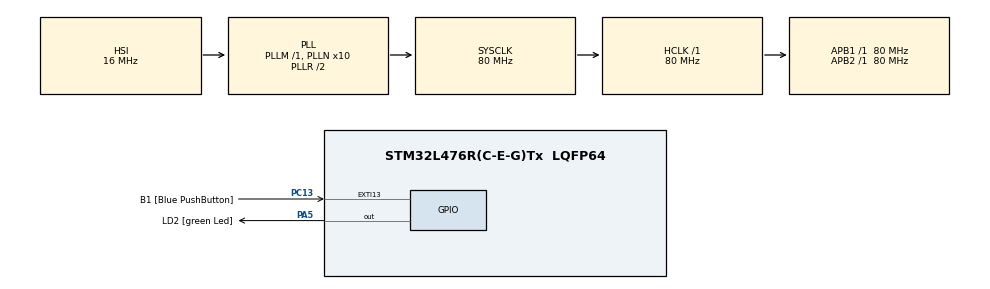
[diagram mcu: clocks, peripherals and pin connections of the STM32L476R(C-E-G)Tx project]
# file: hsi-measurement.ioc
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Mcu.Family=STM32L4
Mcu.Name=STM32L476R(C-E-G)Tx
Mcu.Package=LQFP64
NVIC.PriorityGroup=NVIC_PRIORITYGROUP_4
PA13\ (JTMS-SWDIO).GPIO_Label=TMS
PA13\ (JTMS-SWDIO).Signal=SYS_JTMS-SWDIO
PA14\ (JTCK-SWCLK).GPIO_Label=TCK
PA14\ (JTCK-SWCLK).Signal=SYS_JTCK-SWCLK
PA2.GPIO_Label=USART_TX
PA2.GPIO_Mode=GPIO_MODE_AF_PP
PA2.GPIO_PuPd=GPIO_NOPULL
PA2.GPIO_Speed=GPIO_SPEED_FREQ_VERY_HIGH
PA2.Signal=USART2_TX
PA3.GPIO_Label=USART_RX
PA3.GPIO_Mode=GPIO_MODE_AF_PP
PA3.GPIO_PuPd=GPIO_NOPULL
PA3.GPIO_Speed=GPIO_SPEED_FREQ_VERY_HIGH
PA3.Signal=USART2_RX
PA5.GPIO_Label=LD2 [green Led]
PA5.GPIO_ModeDefaultOutputPP=GPIO_MODE_OUTPUT_PP
PA5.GPIO_PuPd=GPIO_NOPULL
PA5.GPIO_Speed=GPIO_SPEED_FREQ_LOW
PA5.Signal=GPIO_Output
PB3\ (JTDO-TRACESWO).GPIO_Label=SWO
PB3\ (JTDO-TRACESWO).Signal=SYS_JTDO-SWO
PC13.GPIO_Label=B1 [Blue PushButton]
PC13.GPIO_ModeDefaultEXTI=GPIO_MODE_IT_FALLING
PC13.GPIO_PuPd=GPIO_NOPULL
PC13.Signal=GPXTI13
PC14-OSC32_IN\ (PC14).Signal=RCC_OSC32_IN
PC15-OSC32_OUT\ (PC15).Signal=RCC_OSC32_OUT
PH0-OSC_IN\ (PH0).Signal=RCC_OSC_IN
PH1-OSC_OUT\ (PH1).Signal=RCC_OSC_OUT
ProjectManager.HeapSize=0x200
ProjectManager.StackSize=0x400
ProjectManager.TargetToolchain=Makefile
RCC.ADCFreq_Value=64000000
RCC.AHBFreq_Value=80000000
RCC.APB1Freq_Value=80000000
RCC.APB1TimFreq_Value=80000000
RCC.APB2Freq_Value=80000000
RCC.APB2TimFreq_Value=80000000
RCC.CortexFreq_Value=80000000
RCC.HCLKFreq_Value=80000000
RCC.HSE_VALUE=8000000
RCC.HSI_VALUE=16000000
RCC.LSE_VALUE=32768
RCC.MSI_VALUE=4000000
RCC.PLLN=10
RCC.PLLSourceVirtual=RCC_PLLSOURCE_HSI
RCC.PREFETCH_ENABLE=1
RCC.SYSCLKFreq_VALUE=80000000
RCC.SYSCLKSource=RCC_SYSCLKSOURCE_PLLCLK
RCC.USBFreq_Value=64000000
RCC.VCOOutputFreq_Value=160000000
board=NUCLEO-L476RG

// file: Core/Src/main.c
/* USER CODE BEGIN Header */
/**
  ******************************************************************************
  * @file           : main.c
  * @brief          : Main program body
  ******************************************************************************
  * @attention
  *
  * Copyright (c) 2026 STMicroelectronics.
  * All rights reserved.
  *
  * This software is licensed under terms that can be found in the LICENSE file
  * in the root directory of this software component.
  * If no LICENSE file comes with this software, it is provided AS-IS.
  *
  ******************************************************************************
  */
/* USER CODE END Header */
#include "main.h"

/* USER CODE BEGIN PD */
/* L476 addresses from RM0351 (the course's F407 values in the comments) */
#define MY_RCC_BASE    0x40021000UL /* F407: 0x40023800 */
#define MY_GPIOA_BASE  0x48000000UL /* F407: 0x40020000 (AHB1) */

#define MY_RCC_CR      (*(volatile uint32_t *)(MY_RCC_BASE + 0x00UL))
#define MY_RCC_CFGR    (*(volatile uint32_t *)(MY_RCC_BASE + 0x08UL))
#define MY_RCC_AHB2ENR (*(volatile uint32_t *)(MY_RCC_BASE + 0x4CUL)) /* F407: AHB1ENR @ 0x30 */
#define MY_GPIOA_MODER (*(volatile uint32_t *)(MY_GPIOA_BASE + 0x00UL))
#define MY_GPIOA_AFRH  (*(volatile uint32_t *)(MY_GPIOA_BASE + 0x24UL))
/* USER CODE END PD */

void SystemClock_Config(void);
static void MX_GPIO_Init(void);
/* USER CODE BEGIN PFP */
static void mco_output_hsi16(void);
/* USER CODE END PFP */

int main(void)
{

  /* MCU Configuration--------------------------------------------------------*/

  /* Reset of all peripherals, Initializes the Flash interface and the Systick. */
  HAL_Init();

  /* Configure the system clock */
  SystemClock_Config();

  /* Initialize all configured peripherals */
  MX_GPIO_Init();
  /* USER CODE BEGIN 2 */
  mco_output_hsi16();
  /* USER CODE END 2 */

  /* Infinite loop */
  while (1)
  {

  }
}

void SystemClock_Config(void)
{
  RCC_OscInitTypeDef RCC_OscInitStruct = {0};
  RCC_ClkInitTypeDef RCC_ClkInitStruct = {0};

  /** Configure the main internal regulator output voltage
  */
  if (HAL_PWREx_ControlVoltageScaling(PWR_REGULATOR_VOLTAGE_SCALE1) != HAL_OK)
  {
    Error_Handler();
  }

  /** Initializes the RCC Oscillators according to the specified parameters
  * in the RCC_OscInitTypeDef structure.
  */
  RCC_OscInitStruct.OscillatorType = RCC_OSCILLATORTYPE_HSI;
  RCC_OscInitStruct.HSIState = RCC_HSI_ON;
  RCC_OscInitStruct.HSICalibrationValue = RCC_HSICALIBRATION_DEFAULT;
  RCC_OscInitStruct.PLL.PLLState = RCC_PLL_ON;
  RCC_OscInitStruct.PLL.PLLSource = RCC_PLLSOURCE_HSI;
  RCC_OscInitStruct.PLL.PLLM = 1;
  RCC_OscInitStruct.PLL.PLLN = 10;
  RCC_OscInitStruct.PLL.PLLP = RCC_PLLP_DIV7;
  RCC_OscInitStruct.PLL.PLLQ = RCC_PLLQ_DIV2;
  RCC_OscInitStruct.PLL.PLLR = RCC_PLLR_DIV2;
  if (HAL_RCC_OscConfig(&RCC_OscInitStruct) != HAL_OK)
  {
    Error_Handler();
  }

  /** Initializes the CPU, AHB and APB buses clocks
  */
  RCC_ClkInitStruct.ClockType = RCC_CLOCKTYPE_HCLK|RCC_CLOCKTYPE_SYSCLK
                              |RCC_CLOCKTYPE_PCLK1|RCC_CLOCKTYPE_PCLK2;
  RCC_ClkInitStruct.SYSCLKSource = RCC_SYSCLKSOURCE_PLLCLK;
  RCC_ClkInitStruct.AHBCLKDivider = RCC_SYSCLK_DIV1;
  RCC_ClkInitStruct.APB1CLKDivider = RCC_HCLK_DIV1;
  RCC_ClkInitStruct.APB2CLKDivider = RCC_HCLK_DIV1;

  if (HAL_RCC_ClockConfig(&RCC_ClkInitStruct, FLASH_LATENCY_4) != HAL_OK)
  {
    Error_Handler();
  }
}

static void MX_GPIO_Init(void)
{
  GPIO_InitTypeDef GPIO_InitStruct = {0};

  /* GPIO Ports Clock Enable */
  __HAL_RCC_GPIOC_CLK_ENABLE();
  __HAL_RCC_GPIOH_CLK_ENABLE();
  __HAL_RCC_GPIOA_CLK_ENABLE();
  __HAL_RCC_GPIOB_CLK_ENABLE();

  /*Configure GPIO pin Output Level */
  HAL_GPIO_WritePin(LD2_GPIO_Port, LD2_Pin, GPIO_PIN_RESET);

  /*Configure GPIO pin : B1_Pin */
  GPIO_InitStruct.Pin = B1_Pin;
  GPIO_InitStruct.Mode = GPIO_MODE_IT_FALLING;
  GPIO_InitStruct.Pull = GPIO_NOPULL;
  HAL_GPIO_Init(B1_GPIO_Port, &GPIO_InitStruct);

  /*Configure GPIO pins : USART_TX_Pin USART_RX_Pin */
  GPIO_InitStruct.Pin = USART_TX_Pin|USART_RX_Pin;
  GPIO_InitStruct.Mode = GPIO_MODE_AF_PP;
  GPIO_InitStruct.Pull = GPIO_NOPULL;
  GPIO_InitStruct.Speed = GPIO_SPEED_FREQ_VERY_HIGH;
  GPIO_InitStruct.Alternate = GPIO_AF7_USART2;
  HAL_GPIO_Init(GPIOA, &GPIO_InitStruct);

  /*Configure GPIO pin : LD2_Pin */
  GPIO_InitStruct.Pin = LD2_Pin;
  GPIO_InitStruct.Mode = GPIO_MODE_OUTPUT_PP;
  GPIO_InitStruct.Pull = GPIO_NOPULL;
  GPIO_InitStruct.Speed = GPIO_SPEED_FREQ_LOW;
  HAL_GPIO_Init(LD2_GPIO_Port, &GPIO_InitStruct);

}

/* USER CODE BEGIN 4 */
/* HSI16 / 4 = 4 MHz on PA8 (MCO, AF0): Arduino D7, CN9 pin 8.
 * Divided by 4 because PA8 resets to low speed, rated 5 MHz at 50 pF (DS10198 Table 72). */
static void mco_output_hsi16(void)
{
  /* 1. HSI16 is off at reset on the L4: it boots on MSI 4 MHz (RCC_CR resets to 0x63) */
  MY_RCC_CR |= (1UL << 8); /* HSION */
  while (!(MY_RCC_CR & (1UL << 10))) /* HSIRDY */
  {
  }

  /* 2. Prescaler first: RM0351 asks for it to be set before MCO is enabled */
  MY_RCC_CFGR &= ~(0x7UL << 28); /* MCOPRE */
  MY_RCC_CFGR |= (0x2UL << 28);  /* 010: divide by 4 */
  MY_RCC_CFGR &= ~(0xFUL << 24); /* MCOSEL */
  MY_RCC_CFGR |= (0x3UL << 24);  /* 0011: HSI16 */

  /* 3. GPIOA clock; reading it back is the delay RM0351 requires before touching GPIOA */
  MY_RCC_AHB2ENR |= (1UL << 0); /* GPIOAEN */
  (void)MY_RCC_AHB2ENR;

  /* 4. PA8 -> alternate function 0 (MCO, DS10198 Table 17) */
  MY_GPIOA_MODER &= ~(0x3UL << 16);
  MY_GPIOA_MODER |= (0x2UL << 16); /* 10: alternate function */
  MY_GPIOA_AFRH &= ~(0xFUL << 0);  /* AFSEL8 = 0000: AF0 */
}
/* USER CODE END 4 */

void Error_Handler(void)
{
  __disable_irq();
  while (1)
  {
  }
}
